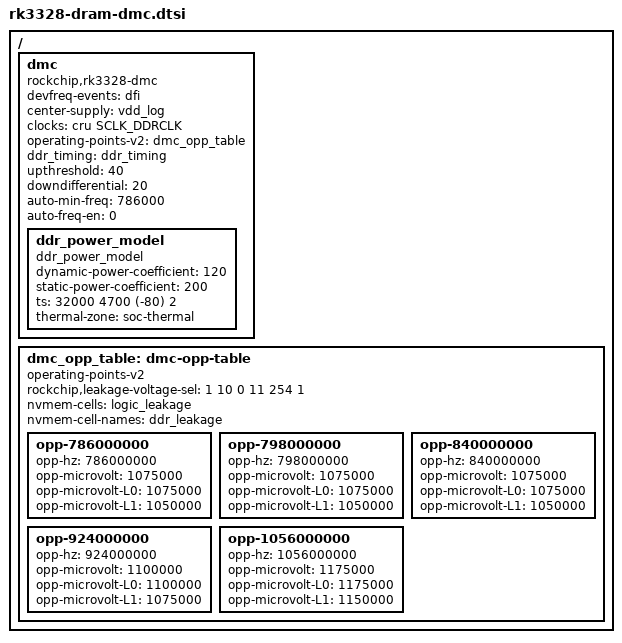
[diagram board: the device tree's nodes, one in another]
// SPDX-License-Identifier: (GPL-2.0+ OR MIT)
/*
 * Copyright (c) 2017 Fuzhou Rockchip Electronics Co., Ltd.
 */

#include "rk3328-dram-default-timing.dtsi"

/ {
	dmc: dmc {
		compatible = "rockchip,rk3328-dmc";
		devfreq-events = <&dfi>;
		center-supply = <&vdd_log>;
		clocks = <&cru SCLK_DDRCLK>;
		clock-names = "dmc_clk";
		operating-points-v2 = <&dmc_opp_table>;
		ddr_timing = <&ddr_timing>;
		upthreshold = <40>;
		downdifferential = <20>;
		auto-min-freq = <786000>;
		auto-freq-en = <0>;
		#cooling-cells = <2>;

		ddr_power_model: ddr_power_model {
			compatible = "ddr_power_model";
			dynamic-power-coefficient = <120>;
			static-power-coefficient = <200>;
			ts = <32000 4700 (-80) 2>;
			thermal-zone = "soc-thermal";
		};
	};

	dmc_opp_table: dmc-opp-table {
		compatible = "operating-points-v2";

		rockchip,leakage-voltage-sel = <
			1   10    0
			11  254   1
		>;
		nvmem-cells = <&logic_leakage>;
		nvmem-cell-names = "ddr_leakage";

		opp-786000000 {
			opp-hz = /bits/ 64 <786000000>;
			opp-microvolt = <1075000>;
			opp-microvolt-L0 = <1075000>;
			opp-microvolt-L1 = <1050000>;
		};
		opp-798000000 {
			opp-hz = /bits/ 64 <798000000>;
			opp-microvolt = <1075000>;
			opp-microvolt-L0 = <1075000>;
			opp-microvolt-L1 = <1050000>;
		};
		opp-840000000 {
			opp-hz = /bits/ 64 <840000000>;
			opp-microvolt = <1075000>;
			opp-microvolt-L0 = <1075000>;
			opp-microvolt-L1 = <1050000>;
		};
		opp-924000000 {
			opp-hz = /bits/ 64 <924000000>;
			opp-microvolt = <1100000>;
			opp-microvolt-L0 = <1100000>;
			opp-microvolt-L1 = <1075000>;
		};
		opp-1056000000 {
			opp-hz = /bits/ 64 <1056000000>;
			opp-microvolt = <1175000>;
			opp-microvolt-L0 = <1175000>;
			opp-microvolt-L1 = <1150000>;
		};
	};
};
